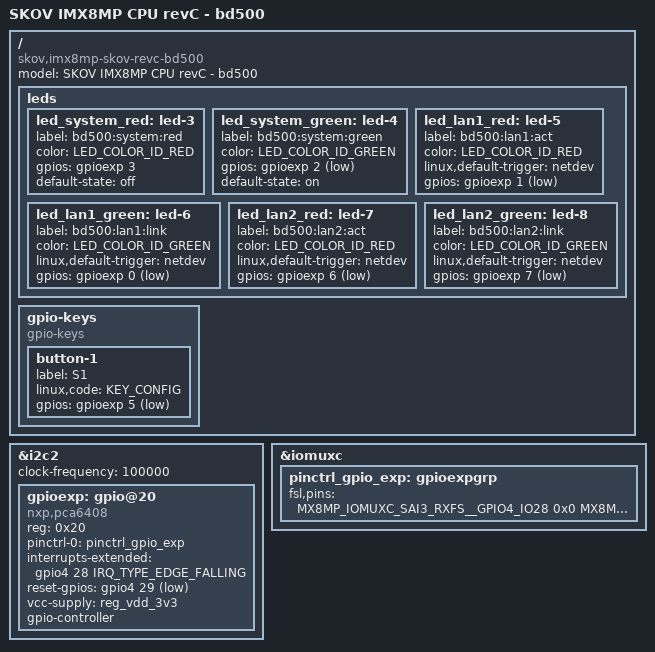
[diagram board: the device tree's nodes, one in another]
// SPDX-License-Identifier: (GPL-2.0 OR MIT)

/dts-v1/;

#include "imx8mp-skov-reva.dtsi"

/ {
	model = "SKOV IMX8MP CPU revC - bd500";
	compatible = "skov,imx8mp-skov-revc-bd500", "fsl,imx8mp";

	leds {
		led_system_red: led-3 {
			label = "bd500:system:red";
			color = <LED_COLOR_ID_RED>;
			/* Inverted compared to others due to NMOS inverter */
			gpios = <&gpioexp 3 GPIO_ACTIVE_HIGH>;
			default-state = "off";
		};

		led_system_green: led-4 {
			label = "bd500:system:green";
			color = <LED_COLOR_ID_GREEN>;
			gpios = <&gpioexp 2 GPIO_ACTIVE_LOW>;
			default-state = "on";
		};

		led_lan1_red: led-5 {
			label = "bd500:lan1:act";
			color = <LED_COLOR_ID_RED>;
			linux,default-trigger = "netdev";
			gpios = <&gpioexp 1 GPIO_ACTIVE_LOW>;
		};

		led_lan1_green: led-6 {
			label = "bd500:lan1:link";
			color = <LED_COLOR_ID_GREEN>;
			linux,default-trigger = "netdev";
			gpios = <&gpioexp 0 GPIO_ACTIVE_LOW>;
		};

		led_lan2_red: led-7 {
			label = "bd500:lan2:act";
			color = <LED_COLOR_ID_RED>;
			linux,default-trigger = "netdev";
			gpios = <&gpioexp 6 GPIO_ACTIVE_LOW>;
		};

		led_lan2_green: led-8 {
			label = "bd500:lan2:link";
			color = <LED_COLOR_ID_GREEN>;
			linux,default-trigger = "netdev";
			gpios = <&gpioexp 7 GPIO_ACTIVE_LOW>;
		};
	};

	gpio-keys {
		compatible = "gpio-keys";

		button-1 {
			label = "S1";
			linux,code = <KEY_CONFIG>;
			gpios = <&gpioexp 5 GPIO_ACTIVE_LOW>;
		};
	};
};

&i2c2 {
	clock-frequency = <100000>;
	status = "okay";

	gpioexp: gpio@20 {
		compatible = "nxp,pca6408";
		reg = <0x20>;
		pinctrl-names = "default";
		pinctrl-0 = <&pinctrl_gpio_exp>;
		interrupts-extended = <&gpio4 28 IRQ_TYPE_EDGE_FALLING>;
		reset-gpios = <&gpio4 29 GPIO_ACTIVE_LOW>;
		vcc-supply = <&reg_vdd_3v3>;
		gpio-controller;
		#gpio-cells = <2>;
	};
};

&iomuxc {
	pinctrl_gpio_exp: gpioexpgrp {
		fsl,pins = <
			MX8MP_IOMUXC_SAI3_RXFS__GPIO4_IO28	0x0
			MX8MP_IOMUXC_SAI3_RXC__GPIO4_IO29	0x0
		>;
	};
};
